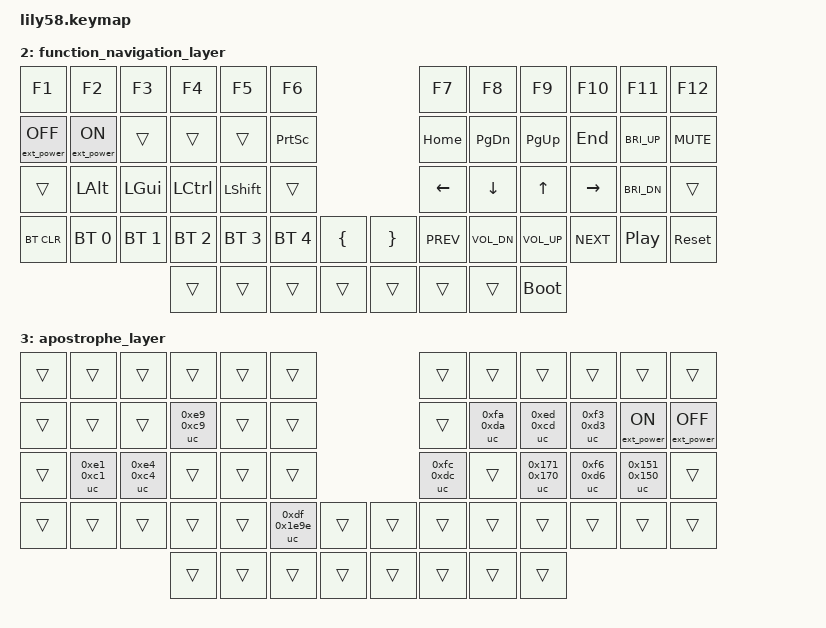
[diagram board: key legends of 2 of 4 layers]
/*
 * Copyright (c) 2020 The ZMK Contributors
 *
 * SPDX-License-Identifier: MIT
 */

#include <behaviors.dtsi>
#include <dt-bindings/zmk/keys.h>
#include <dt-bindings/zmk/bt.h>
#include <dt-bindings/zmk/ext_power.h>
#include <dt-bindings/zmk/outputs.h>
#include <behaviors/unicode.dtsi>

// Home row mods macro 
#define HRML(k1,k2,k3,k4) &ht LALT k1  &ht LGUI k2  &ht LCTRL k3  &ht LSHFT k4
#define HRMR(k1,k2,k3,k4) &ht RSHFT k1  &ht RCTRL k2  &ht RGUI k3  &ht RALT k4

/* Outside root node */
&uc {
    default-mode = <UC_MODE_WIN_COMPOSE>;
	minimum-length = <4>;
	win-compose-key = <LALT>;
};


/ {
    behaviors {
        ht: hold_tap {
            //label = "hold_tap";
            compatible = "zmk,behavior-hold-tap";
            #binding-cells = <2>;
            flavor = "tap-preferred";
            tapping-term-ms = <170>;
            quick-tap-ms = <120>;
            //global-quick-tap;
            bindings = <&kp>, <&kp>;
        };
    };

    
    keymap {
        compatible = "zmk,keymap";

        // 0
        default_layer {
// ------------------------------------------------------------------------------------------------------------
// |  ESC  |  1  |  2  |  3   |  4   |  5   |                   |  6   |  7    |  8    |  9   |   0   |   =S+ |
// |  TAB  |  Q  |  W  |  E   |  R   |  T   |                   |  Y   |  U    |  I    |  O   |   P   |   -S_ |
// |       |  A  |  S  |  D   |  F   |  G   |                   |  H   |  J    |  K    |  L   |   ;S: | \S"\" |
// |  MO 4 |  Z  |  X  |  C   |  V   |  B   | "["    |  |  "]"  |  N   |  M    |  ,S<  |  .S> |   /S? |   'S" |
//                     | CAPS |  MO2 | MO1  |  SPACE |  | ENTER | MO3  | BSPC  |  DEL  |
            bindings = <
&trans	  &kp N1 &kp N2  &kp N3   &kp N4   &kp N5                     &kp N6 &kp N7   &kp N8    &kp N9  &kp N0   &kp EQUAL
&kp TAB   &kp Q  &kp W   &kp E    &kp R    &kp T                      &kp Y  &kp U    &kp I     &kp O   &kp P    &kp MINUS
&kp ESC   HRML(A,S,      D,       F)       &kp G                      &kp H  HRMR(J,  K,        L,      SEMI)    &kp BSLH
&trans    &kp Z  &kp X   &kp C    &kp V    &kp B  &kp LBKT   &kp RBKT &kp N  &kp M    &kp COMMA &kp DOT &kp FSLH &kp SQT
                         &kp CAPS &mo 3    &mo 1  &kp SPACE  &kp RET  &mo 2  &kp BSPC &kp DELETE
            >;
        };

        // 1
        symbol_layer {
// ------------------------------------------------------------------------------------------------------------
// |  RST  |      |     |      |      |      |                   |  U˘  |  U°   |  U˛   |      |       |       |
// |       |  1   |  2  |  3   |  4   |  5   |                   |  6   |  7    |  8    |  9   |   0   |       |
// |   `   |  !   |  @  |  #   |  $   |  %   |                   |  ^   |  &    |  *    |  (   |   )   |   ~   |
// |   U§  |      |     |      |      |      |    (   |  |   )   |  Uˇ  |  _    |  +    |  {   |   }   |  "|"  |
//                      | BOOT |      |      |        |  |       |      |       |       |
            bindings = <
&sys_reset &trans   &trans &trans      &trans   &trans                       &trans    &trans    &trans    &trans   &trans   &trans
&trans     &kp N1   &kp N2  &kp N3      &kp N4  &kp N5                       &kp N6    &kp N7    &kp N8    &kp N9   &kp N0   &trans
&kp GRAVE  HRML(EXCL,AT,    HASH,       DOLLAR) &kp PRCNT                    &kp CARET HRML(AMPS,ASTRK,    LPAR,    RPAR)    &kp TILDE
&trans     &trans   &trans  &trans      &trans  &trans    &kp LPAR  &kp RPAR &trans    &kp UNDER &kp PLUS  &kp LBRC &kp RBRC &kp PIPE
                            &bootloader &trans  &trans    &trans    &trans   &trans    &trans    &trans
            >;
        };

        // 2
        function_navigation_layer {
// ------------------------------------------------------------------------------------------------------------
// |   F1  |  F2   |  F3   |  F4  |  F5  |  F6  |                   |   F7  |  F8   |  F9   |  F10 |  F11  |  F12  | 
// | EP_OFF|  EP_ON|       |      |      |PRTSCR|                   |  HOME | PGDWN | PGUP  |  END |  BRIU | MUTE  |
// |       |  ALT  | GUI   | CTRL | SHFT |      |                   |   <-  |   v   |  ^    |  ->  |  BRID |       |
// | BTCLR | BT1   | BT2   |  BT3 |  BT4 |  BT5 |  "{"   |  |  "}"  |  PREV |  VOLD |  VOLU | NEXT | PAUSE |  RST  |
//                         |      |      |      |        |  |       |       |       | BOOT  |
            bindings = <
&kp F1            &kp F2           &kp F3       &kp F4       &kp F5       &kp F6                            &kp F7     &kp F8     &kp F9     &kp F10    &kp F11      &kp F12
&ext_power EP_OFF &ext_power EP_ON &trans       &trans       &trans       &kp PSCRN                         &kp HOME   &kp PG_DN  &kp PG_UP  &kp END    &kp C_BRI_UP &kp C_MUTE
&trans            &kp LALT         &kp LGUI     &kp LCTRL    &kp LSHFT    &trans                            &kp LEFT   &kp DOWN   &kp UP     &kp RIGHT  &kp C_BRI_DN &trans
&bt BT_CLR        &bt BT_SEL 0     &bt BT_SEL 1 &bt BT_SEL 2 &bt BT_SEL 3 &bt BT_SEL 4  &kp LBRC   &kp RBRC &kp C_PREV &kp C_VOL_DN &kp C_VOL_UP &kp C_NEXT &kp C_PP &sys_reset
                                                &trans       &trans       &trans        &trans     &trans   &trans     &trans     &bootloader
            >;
        };

        // 3
        apostrophe_layer {
// ------------------------------------------------------------------------------------------------------------
// |       |     |     |      |      |      |                   |      |       |       |      |       |       |
// |       |     |     |  É   |      |      |                   |      |  Ú    |  Í    |  Ó   | EP_ON | EP_OFF|
// |       |  Á  |     |      |      |      |                   |      |  Ü    |  Ű    |  Ö   |  Ő    |       |
// |       |     |     |      |      |      |        |  |       |      |       |       |      |       |       |
//                     |      |      |      |        |  |       |      |       |       |
            bindings = <
&trans &trans		 &trans        &trans		  &trans &trans                 &trans		  &trans		&trans			&trans        &trans          &trans
&trans &trans		 &trans        &uc 0xe9 0xc9  &trans &trans                 &trans		  &uc 0xfa 0xda &uc 0xed 0xcd   &uc 0xf3 0xd3 &ext_power      EP_ON &ext_power EP_OFF
&trans &uc 0xe1 0xc1 &uc 0xe4 0xc4 &trans         &trans &trans                 &uc 0xfc 0xdc &trans     &uc 0x171 0x170 &uc 0xf6 0xd6 &uc 0x151 0x150 &trans
&trans &trans		 &trans        &trans		  &trans &uc 0xdf 0x1e9e &trans   &trans &trans		  &trans		&trans			&trans		  &trans          &trans
							       &trans		  &trans &trans &trans   &trans &trans		  &trans		&trans
            >;
        };
    };
};
